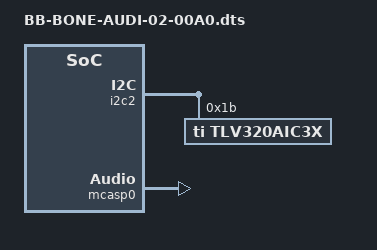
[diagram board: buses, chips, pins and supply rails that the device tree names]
/*
 * Copyright (C) 2012 Texas Instruments Incorporated - http://www.ti.com/
 *
 * This program is free software; you can redistribute it and/or modify
 * it under the terms of the GNU General Public License version 2 as
 * published by the Free Software Foundation.
 */
/dts-v1/;
/plugin/;

/ {
	compatible = "ti,beaglebone-black";

	/* identification */
	part-number = "BB-BONE-AUDI-02";
	version = "00A0";

	/* state the resources this cape uses */
	exclusive-use =
		/* the pin header uses */
		"P9.25",	/* mcasp0: mcasp0_ahclkx */
		"P9.28",	/* mcasp0: mcasp0_axr2 */
		"P9.29",	/* mcasp0: mcasp0_fsx */
		"P9.30", 	/* mcasp0: mcasp0_axr0 */
		"P9.31",	/* mcasp0: mcasp0_aclkx */
		/* the hardware ip uses */
		"mcasp0";

	fragment@0 {
		target = <&am33xx_pinmux>;
		__overlay__ {

			bone_audio_cape_audio_pins: pinmux_bone_audio_cape_audio_pins {
				pinctrl-single,pins = <
					0x1ac 0x20	/* mcasp0_ahclkx, INPUT | MODE0 */
					0x19c 0x22	/* mcasp0_axr2, INPUT | MODE2 */
					0x194 0x20	/* mcasp0_fsx, INPUT | MODE0 */
					0x198 0x08	/* mcasp0_axr0, OUTPUT | MODE0 */
					0x190 0x20	/* mcasp0_aclkx, INPUT | MODE0 */
				>;
			};
		};
	};


	fragment@1 {
		target = <&i2c2>;
		__overlay__ {
			#address-cells = <1>;
			#size-cells = <0>;

			tlv320aic3x: tlv320aic3x@1b {
				compatible = "ti,tlv320aic3x";
				reg = <0x1b>;
				status = "okay";
			};
		};
	};

	fragment@2 {
		target = <&mcasp0>;
		__overlay__ {
			pinctrl-names = "default";
			pinctrl-0 = <&bone_audio_cape_audio_pins>;

			status = "okay";

			op-mode = <0>;          /* MCASP_IIS_MODE */
			tdm-slots = <2>;
			num-serializer = <16>;
			serial-dir = <  /* 0: INACTIVE, 1: TX, 2: RX */
				1 0 2 0
				0 0 0 0
				0 0 0 0
				0 0 0 0
			>;
			tx-num-evt = <1>;
			rx-num-evt = <1>;
		};
	};

	fragment@3 {
		target = <&ocp>;
		__overlay__ {
			sound {
				compatible = "ti,da830-evm-audio";
				ti,model = "DA830 EVM";
				ti,audio-codec = <&tlv320aic3x>;
				ti,mcasp-controller = <&mcasp0>;
				ti,codec-clock-rate = <12000000>;
				ti,audio-routing =
					"Headphone Jack",       "HPLOUT",
					"Headphone Jack",       "HPROUT",
					"Line Out",             "LLOUT",
					"Line Out",             "RLOUT",
					"MIC3L",                "Mic Bias 2V",
					"MIC3R",                "Mic Bias 2V",
					"Mic Bias 2V",          "Mic Jack",
					"LINE1L",               "Line In",
					"LINE2L",               "Line In",
					"LINE1R",               "Line In",
					"LINE2R",               "Line In";
			};
		};

	};
};
